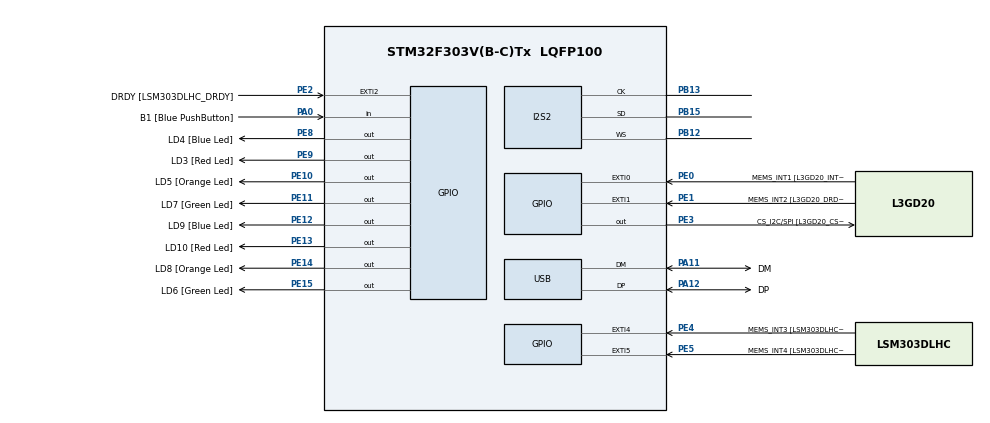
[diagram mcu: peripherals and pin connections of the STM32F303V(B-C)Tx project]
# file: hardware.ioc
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I2S2.AudioFreq-Half_Duplex_Master=I2S_AUDIOFREQ_48K
I2S2.DataFormat-Half_Duplex_Master=I2S_DATAFORMAT_24B
I2S2.ErrorAudioFreq-Half_Duplex_Master=1.9 %
I2S2.RealAudioFreq-Half_Duplex_Master=48.913 KHz
Mcu.Family=STM32F3
Mcu.Name=STM32F303V(B-C)Tx
Mcu.Package=LQFP100
NVIC.PriorityGroup=NVIC_PRIORITYGROUP_0
NVIC.USB_LP_CAN_RX0_IRQn=true\:0\:0
PA0.GPIO_Label=B1 [Blue PushButton]
PA0.GPIO_Mode=GPIO_MODE_INPUT
PA0.GPIO_PuPd=GPIO_NOPULL
PA0.Signal=GPIO_Input
PA11.GPIO_Label=DM
PA11.GPIO_Mode=GPIO_MODE_AF_PP
PA11.GPIO_PuPd=GPIO_NOPULL
PA11.GPIO_Speed=GPIO_SPEED_LOW
PA11.Mode=Device
PA11.Signal=USB_DM
PA12.GPIO_Label=DP
PA12.GPIO_Mode=GPIO_MODE_AF_PP
PA12.GPIO_PuPd=GPIO_NOPULL
PA12.GPIO_Speed=GPIO_SPEED_LOW
PA12.Mode=Device
PA12.Signal=USB_DP
PA13.GPIO_Label=SWDIO
PA13.Mode=Trace-Asynchronous_SW
PA13.Signal=SYS_JTMS-SWDIO
PA14.GPIO_Label=SWCLK
PA14.Mode=Trace-Asynchronous_SW
PA14.Signal=SYS_JTCK-SWCLK
PA5.GPIO_Label=SPI1_SCK [L3GD20_SCL/SPC]
PA5.GPIO_Mode=GPIO_MODE_AF_PP
PA5.GPIO_PuPd=GPIO_NOPULL
PA5.GPIO_Speed=GPIO_SPEED_LOW
PA5.Signal=SPI1_SCK
PA6.GPIO_Label=SPI1_MISO [L3GD20_SA0/SDO]
PA6.GPIO_Mode=GPIO_MODE_AF_PP
PA6.GPIO_PuPd=GPIO_NOPULL
PA6.GPIO_Speed=GPIO_SPEED_LOW
PA6.Signal=SPI1_MISO
PA7.GPIO_Label=SPI1_MISO [L3GD20_SDA/SDI/SDO]
PA7.GPIO_Mode=GPIO_MODE_AF_PP
PA7.GPIO_PuPd=GPIO_NOPULL
PA7.GPIO_Speed=GPIO_SPEED_LOW
PA7.Signal=SPI1_MOSI
PB12.Mode=Half_Duplex_Master
PB12.Signal=I2S2_WS
PB13.Mode=Half_Duplex_Master
PB13.Signal=I2S2_CK
PB15.Mode=Half_Duplex_Master
PB15.Signal=I2S2_SD
PB3.GPIO_Label=SWO
PB3.Mode=Trace-Asynchronous_SW
PB3.Signal=SYS_JTDO-TRACESWO
PB6.GPIO_FM6=__NULL
PB6.GPIO_Label=I2C1_SCL [LSM303DLHC_SCL]
PB6.GPIO_Mode=GPIO_MODE_AF_OD
PB6.GPIO_PuPd=GPIO_NOPULL
PB6.GPIO_Speed=GPIO_SPEED_LOW
PB6.Signal=I2C1_SCL
PB7.GPIO_FM7=__NULL
PB7.GPIO_Label=I2C1_SDA [LSM303DLHC_SDA]
PB7.GPIO_Mode=GPIO_MODE_AF_OD
PB7.GPIO_PuPd=GPIO_NOPULL
PB7.GPIO_Speed=GPIO_SPEED_LOW
PB7.Signal=I2C1_SDA
PC14-OSC32_IN.GPIO_Label=OSC32_IN
PC14-OSC32_IN.Signal=RCC_OSC32_IN
PC15-OSC32_OUT.GPIO_Label=OSC32_OUT
PC15-OSC32_OUT.Signal=RCC_OSC32_OUT
PE0.GPIO_Label=MEMS_INT1 [L3GD20_INT1]
PE0.GPIO_ModeDefaultEXTI=GPIO_MODE_EVT_RISING
PE0.GPIO_PuPd=GPIO_NOPULL
PE0.Signal=GPXTI0
PE1.GPIO_Label=MEMS_INT2 [L3GD20_DRDY/INT2]
PE1.GPIO_ModeDefaultEXTI=GPIO_MODE_EVT_RISING
PE1.GPIO_PuPd=GPIO_NOPULL
PE1.Signal=GPXTI1
PE10.GPIO_Label=LD5 [Orange Led]
PE10.GPIO_ModeDefaultOutputPP=GPIO_MODE_OUTPUT_PP
PE10.GPIO_PuPd=GPIO_NOPULL
PE10.GPIO_Speed=GPIO_SPEED_LOW
PE10.Signal=GPIO_Output
PE11.GPIO_Label=LD7 [Green Led]
PE11.GPIO_ModeDefaultOutputPP=GPIO_MODE_OUTPUT_PP
PE11.GPIO_PuPd=GPIO_NOPULL
PE11.GPIO_Speed=GPIO_SPEED_LOW
PE11.Signal=GPIO_Output
PE12.GPIO_Label=LD9 [Blue Led]
PE12.GPIO_ModeDefaultOutputPP=GPIO_MODE_OUTPUT_PP
PE12.GPIO_PuPd=GPIO_NOPULL
PE12.GPIO_Speed=GPIO_SPEED_LOW
PE12.Signal=GPIO_Output
PE13.GPIO_Label=LD10 [Red Led]
PE13.GPIO_ModeDefaultOutputPP=GPIO_MODE_OUTPUT_PP
PE13.GPIO_PuPd=GPIO_NOPULL
PE13.GPIO_Speed=GPIO_SPEED_LOW
PE13.Signal=GPIO_Output
PE14.GPIO_Label=LD8 [Orange Led]
PE14.GPIO_ModeDefaultOutputPP=GPIO_MODE_OUTPUT_PP
PE14.GPIO_PuPd=GPIO_NOPULL
PE14.GPIO_Speed=GPIO_SPEED_LOW
PE14.Signal=GPIO_Output
PE15.GPIO_Label=LD6 [Green Led]
PE15.GPIO_ModeDefaultOutputPP=GPIO_MODE_OUTPUT_PP
PE15.GPIO_PuPd=GPIO_NOPULL
PE15.GPIO_Speed=GPIO_SPEED_LOW
PE15.Signal=GPIO_Output
PE2.GPIO_Label=DRDY [LSM303DLHC_DRDY]
PE2.GPIO_ModeDefaultEXTI=GPIO_MODE_EVT_RISING
PE2.GPIO_PuPd=GPIO_NOPULL
PE2.Signal=GPXTI2
PE3.GPIO_Label=CS_I2C/SPI [L3GD20_CS_I2C/SPI]
PE3.GPIO_ModeDefaultOutputPP=GPIO_MODE_OUTPUT_PP
PE3.GPIO_PuPd=GPIO_NOPULL
PE3.GPIO_Speed=GPIO_SPEED_LOW
PE3.Signal=GPIO_Output
PE4.GPIO_Label=MEMS_INT3 [LSM303DLHC_INT1]
PE4.GPIO_ModeDefaultEXTI=GPIO_MODE_EVT_RISING
PE4.GPIO_PuPd=GPIO_NOPULL
PE4.Signal=GPXTI4
PE5.GPIO_Label=MEMS_INT4 [LSM303DLHC_INT2]
PE5.GPIO_ModeDefaultEXTI=GPIO_MODE_EVT_RISING
PE5.GPIO_PuPd=GPIO_NOPULL
PE5.Signal=GPXTI5
PE8.GPIO_Label=LD4 [Blue Led]
PE8.GPIO_ModeDefaultOutputPP=GPIO_MODE_OUTPUT_PP
PE8.GPIO_PuPd=GPIO_NOPULL
PE8.GPIO_Speed=GPIO_SPEED_LOW
PE8.Signal=GPIO_Output
PE9.GPIO_Label=LD3 [Red Led]
PE9.GPIO_ModeDefaultOutputPP=GPIO_MODE_OUTPUT_PP
PE9.GPIO_PuPd=GPIO_NOPULL
PE9.GPIO_Speed=GPIO_SPEED_LOW
PE9.Signal=GPIO_Output
PF0-OSC_IN.GPIO_Label=OSC_IN
PF0-OSC_IN.Mode=HSE-External-Clock-Source
PF0-OSC_IN.Signal=RCC_OSC_IN
PF1-OSC_OUT.GPIO_Label=OSC_OUT
PF1-OSC_OUT.Signal=RCC_OSC_OUT
ProjectManager.TargetToolchain=TrueSTUDIO 4.3.1
RCC.APB1CLKDivider=RCC_HCLK_DIV2
RCC.EXTERNAL_CLOCK_VALUE=11289600
RCC.HSE_VALUE=8000000
RCC.HSI_VALUE=8000000
RCC.LSE_VALUE=32768
RCC.PLLMUL=RCC_PLL_MUL9
RCC.PLLSource=RCC_PLLSOURCE_HSE
RCC.PRESCALERUSB=RCC_USBPLLCLK_DIV1_5
RCC.SYSCLKSource=RCC_SYSCLKSOURCE_PLLCLK
USB.ep0_mps=DEP0CTL_MPS_32

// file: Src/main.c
/**
  ******************************************************************************
  * File Name          : main.c
  * Date               : 30/09/2014 22:32:24
  * Description        : Main program body
  ******************************************************************************
  *
  * COPYRIGHT(c) 2014 STMicroelectronics
  *
  * Redistribution and use in source and binary forms, with or without modification,
  * are permitted provided that the following conditions are met:
  *   1. Redistributions of source code must retain the above copyright notice,
  *      this list of conditions and the following disclaimer.
  *   2. Redistributions in binary form must reproduce the above copyright notice,
  *      this list of conditions and the following disclaimer in the documentation
  *      and/or other materials provided with the distribution.
  *   3. Neither the name of STMicroelectronics nor the names of its contributors
  *      may be used to endorse or promote products derived from this software
  *      without specific prior written permission.
  *
  * THIS SOFTWARE IS PROVIDED BY THE COPYRIGHT HOLDERS AND CONTRIBUTORS "AS IS"
  * AND ANY EXPRESS OR IMPLIED WARRANTIES, INCLUDING, BUT NOT LIMITED TO, THE
  * IMPLIED WARRANTIES OF MERCHANTABILITY AND FITNESS FOR A PARTICULAR PURPOSE ARE
  * DISCLAIMED. IN NO EVENT SHALL THE COPYRIGHT HOLDER OR CONTRIBUTORS BE LIABLE
  * FOR ANY DIRECT, INDIRECT, INCIDENTAL, SPECIAL, EXEMPLARY, OR CONSEQUENTIAL
  * DAMAGES (INCLUDING, BUT NOT LIMITED TO, PROCUREMENT OF SUBSTITUTE GOODS OR
  * SERVICES; LOSS OF USE, DATA, OR PROFITS; OR BUSINESS INTERRUPTION) HOWEVER
  * CAUSED AND ON ANY THEORY OF LIABILITY, WHETHER IN CONTRACT, STRICT LIABILITY,
  * OR TORT (INCLUDING NEGLIGENCE OR OTHERWISE) ARISING IN ANY WAY OUT OF THE USE
  * OF THIS SOFTWARE, EVEN IF ADVISED OF THE POSSIBILITY OF SUCH DAMAGE.
  *
  ******************************************************************************
  */

#include "stm32f3xx_hal.h"

I2S_HandleTypeDef hi2s2;

PCD_HandleTypeDef hpcd_USB_FS;

/* USER CODE BEGIN 0 */
extern void setup(void);
extern void loop(void);
/* USER CODE END 0 */

void SystemClock_Config(void);
static void MX_GPIO_Init(void);
static void MX_I2S2_Init(void);
static void MX_USB_PCD_Init(void);

int main(void)
{

  /* MCU Configuration----------------------------------------------------------*/

  /* Reset of all peripherals, Initializes the Flash interface and the Systick. */
  HAL_Init();

  /* Configure the system clock */
  SystemClock_Config();

  /* System interrupt init*/
  /* Sets the priority grouping field */
  HAL_NVIC_SetPriorityGrouping(NVIC_PRIORITYGROUP_0);
  HAL_NVIC_SetPriority(SysTick_IRQn, 0, 0);

  /* Initialize all configured peripherals */
  MX_GPIO_Init();
  MX_I2S2_Init();
  MX_USB_PCD_Init();

  /* USER CODE BEGIN 2 */
  setup();
  /* USER CODE END 2 */

  /* USER CODE BEGIN 3 */
  /* Infinite loop */
  while (1)
  {
    loop();
  }
  /* USER CODE END 3 */

}

/** System Clock Configuration
*/
void SystemClock_Config(void)
{

  RCC_ClkInitTypeDef RCC_ClkInitStruct;
  RCC_PeriphCLKInitTypeDef PeriphClkInit;
  RCC_OscInitTypeDef RCC_OscInitStruct;

  RCC_OscInitStruct.OscillatorType = RCC_OSCILLATORTYPE_HSE;
  RCC_OscInitStruct.HSEState = RCC_HSE_BYPASS;
  RCC_OscInitStruct.HSEPredivValue = RCC_HSE_PREDIV_DIV1;
  RCC_OscInitStruct.PLL.PLLState = RCC_PLL_ON;
  RCC_OscInitStruct.PLL.PLLSource = RCC_PLLSOURCE_HSE;
  RCC_OscInitStruct.PLL.PLLMUL = RCC_PLL_MUL9;
  HAL_RCC_OscConfig(&RCC_OscInitStruct);

  RCC_ClkInitStruct.ClockType = RCC_CLOCKTYPE_SYSCLK|RCC_CLOCKTYPE_PCLK1;
  RCC_ClkInitStruct.SYSCLKSource = RCC_SYSCLKSOURCE_PLLCLK;
  RCC_ClkInitStruct.AHBCLKDivider = RCC_SYSCLK_DIV1;
  RCC_ClkInitStruct.APB1CLKDivider = RCC_HCLK_DIV2;
  RCC_ClkInitStruct.APB2CLKDivider = RCC_HCLK_DIV1;
  HAL_RCC_ClockConfig(&RCC_ClkInitStruct, FLASH_LATENCY_2);

  PeriphClkInit.PeriphClockSelection = RCC_PERIPHCLK_USB;
  PeriphClkInit.USBClockSelection = RCC_USBPLLCLK_DIV1_5;
  HAL_RCCEx_PeriphCLKConfig(&PeriphClkInit);

  __SYSCFG_CLK_ENABLE();

}

/* I2S2 init function */
void MX_I2S2_Init(void)
{

  hi2s2.Instance = SPI2;
  hi2s2.Init.Mode = I2S_MODE_MASTER_TX;
  hi2s2.Init.Standard = I2S_STANDARD_PHILIPS;
  hi2s2.Init.DataFormat = I2S_DATAFORMAT_24B;
  hi2s2.Init.MCLKOutput = I2S_MCLKOUTPUT_DISABLE;
  hi2s2.Init.AudioFreq = I2S_AUDIOFREQ_48K;
  hi2s2.Init.CPOL = I2S_CPOL_LOW;
  hi2s2.Init.ClockSource = I2S_CLOCK_SYSCLK;
  hi2s2.Init.FullDuplexMode = I2S_FULLDUPLEXMODE_DISABLE;
  HAL_I2S_Init(&hi2s2);

}

/* USB init function */
void MX_USB_PCD_Init(void)
{

  hpcd_USB_FS.Instance = USB;
  hpcd_USB_FS.Init.dev_endpoints = 8;
  hpcd_USB_FS.Init.speed = PCD_SPEED_FULL;
  hpcd_USB_FS.Init.ep0_mps = DEP0CTL_MPS_32;
  hpcd_USB_FS.Init.phy_itface = PCD_PHY_EMBEDDED;
  hpcd_USB_FS.Init.Sof_enable = DISABLE;
  hpcd_USB_FS.Init.low_power_enable = DISABLE;
  hpcd_USB_FS.Init.battery_charging_enable = DISABLE;
  HAL_PCD_Init(&hpcd_USB_FS);

}

/** Configure pins as
        * Analog
        * Input
        * Output
        * EVENT_OUT
        * EXTI
     PA5   ------> SPI1_SCK
     PA6   ------> SPI1_MISO
     PA7   ------> SPI1_MOSI
     PB6   ------> I2C1_SCL
     PB7   ------> I2C1_SDA
*/
void MX_GPIO_Init(void)
{

  GPIO_InitTypeDef GPIO_InitStruct;

  /* GPIO Ports Clock Enable */
  __GPIOE_CLK_ENABLE();
  __GPIOC_CLK_ENABLE();
  __GPIOF_CLK_ENABLE();
  __GPIOA_CLK_ENABLE();
  __GPIOB_CLK_ENABLE();

  /*Configure GPIO pins : PE2 PE4 PE5 PE0
                           PE1 */
  GPIO_InitStruct.Pin = GPIO_PIN_2|GPIO_PIN_4|GPIO_PIN_5|GPIO_PIN_0
                          |GPIO_PIN_1;
  GPIO_InitStruct.Mode = GPIO_MODE_EVT_RISING;
  GPIO_InitStruct.Pull = GPIO_NOPULL;
  HAL_GPIO_Init(GPIOE, &GPIO_InitStruct);

  /*Configure GPIO pins : PE3 PE8 PE9 PE10
                           PE11 PE12 PE13 PE14
                           PE15 */
  GPIO_InitStruct.Pin = GPIO_PIN_3|GPIO_PIN_8|GPIO_PIN_9|GPIO_PIN_10
                          |GPIO_PIN_11|GPIO_PIN_12|GPIO_PIN_13|GPIO_PIN_14
                          |GPIO_PIN_15;
  GPIO_InitStruct.Mode = GPIO_MODE_OUTPUT_PP;
  GPIO_InitStruct.Pull = GPIO_NOPULL;
  GPIO_InitStruct.Speed = GPIO_SPEED_LOW;
  HAL_GPIO_Init(GPIOE, &GPIO_InitStruct);

  /*Configure GPIO pin : PA0 */
  GPIO_InitStruct.Pin = GPIO_PIN_0;
  GPIO_InitStruct.Mode = GPIO_MODE_INPUT;
  GPIO_InitStruct.Pull = GPIO_NOPULL;
  HAL_GPIO_Init(GPIOA, &GPIO_InitStruct);

  /*Configure GPIO pins : PA5 PA6 PA7 */
  GPIO_InitStruct.Pin = GPIO_PIN_5|GPIO_PIN_6|GPIO_PIN_7;
  GPIO_InitStruct.Mode = GPIO_MODE_AF_PP;
  GPIO_InitStruct.Pull = GPIO_NOPULL;
  GPIO_InitStruct.Speed = GPIO_SPEED_LOW;
  GPIO_InitStruct.Alternate = GPIO_AF5_SPI1;
  HAL_GPIO_Init(GPIOA, &GPIO_InitStruct);

  /*Configure GPIO pins : PB6 PB7 */
  GPIO_InitStruct.Pin = GPIO_PIN_6|GPIO_PIN_7;
  GPIO_InitStruct.Mode = GPIO_MODE_AF_OD;
  GPIO_InitStruct.Pull = GPIO_NOPULL;
  GPIO_InitStruct.Speed = GPIO_SPEED_LOW;
  GPIO_InitStruct.Alternate = GPIO_AF4_I2C1;
  HAL_GPIO_Init(GPIOB, &GPIO_InitStruct);

}

/************************ (C) COPYRIGHT STMicroelectronics *****END OF FILE****/
